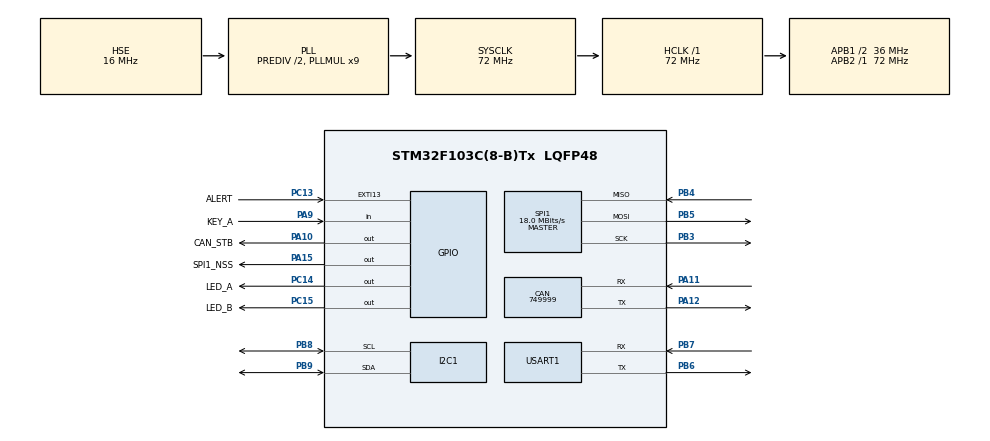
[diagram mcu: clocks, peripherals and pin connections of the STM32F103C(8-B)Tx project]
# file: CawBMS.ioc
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CAN.CalculateBaudRate=749999
CAN.CalculateTimeBit=1333
CAN.CalculateTimeQuantum=444.44444444444446
Mcu.Family=STM32F1
Mcu.Name=STM32F103C(8-B)Tx
Mcu.Package=LQFP48
NVIC.PriorityGroup=NVIC_PRIORITYGROUP_4
PA10.GPIO_Label=CAN_STB
PA10.PinState=GPIO_PIN_SET
PA10.Signal=GPIO_Output
PA11.Mode=CAN_Activate
PA11.Signal=CAN_RX
PA12.Mode=CAN_Activate
PA12.Signal=CAN_TX
PA13.Mode=Serial_Wire
PA13.Signal=SYS_JTMS-SWDIO
PA14.Mode=Serial_Wire
PA14.Signal=SYS_JTCK-SWCLK
PA15.GPIO_Label=SPI1_NSS
PA15.Signal=GPIO_Output
PA9.GPIO_Label=KEY_A
PA9.GPIO_PuPd=GPIO_PULLUP
PA9.Signal=GPIO_Input
PB3.Mode=Full_Duplex_Master
PB3.Signal=SPI1_SCK
PB4.Mode=Full_Duplex_Master
PB4.Signal=SPI1_MISO
PB5.Mode=Full_Duplex_Master
PB5.Signal=SPI1_MOSI
PB6.Mode=Asynchronous
PB6.Signal=USART1_TX
PB7.Mode=Asynchronous
PB7.Signal=USART1_RX
PB8.GPIO_Speed=GPIO_SPEED_FREQ_HIGH
PB8.Mode=I2C
PB8.Signal=I2C1_SCL
PB9.GPIO_Speed=GPIO_SPEED_FREQ_HIGH
PB9.Mode=I2C
PB9.Signal=I2C1_SDA
PC13-TAMPER-RTC.GPIO_Label=ALERT
PC13-TAMPER-RTC.Signal=GPXTI13
PC14-OSC32_IN.GPIO_Label=LED_A
PC14-OSC32_IN.PinState=GPIO_PIN_SET
PC14-OSC32_IN.Signal=GPIO_Output
PC15-OSC32_OUT.GPIO_Label=LED_B
PC15-OSC32_OUT.PinState=GPIO_PIN_SET
PC15-OSC32_OUT.Signal=GPIO_Output
PD0-OSC_IN.Mode=HSE-External-Oscillator
PD0-OSC_IN.Signal=RCC_OSC_IN
PD1-OSC_OUT.Mode=HSE-External-Oscillator
PD1-OSC_OUT.Signal=RCC_OSC_OUT
ProjectManager.HeapSize=0x200
ProjectManager.StackSize=0x400
ProjectManager.TargetToolchain=Makefile
RCC.AHBFreq_Value=72000000
RCC.APB1CLKDivider=RCC_HCLK_DIV2
RCC.APB1Freq_Value=36000000
RCC.APB1TimFreq_Value=72000000
RCC.APB2Freq_Value=72000000
RCC.APB2TimFreq_Value=72000000
RCC.HCLKFreq_Value=72000000
RCC.HSEDivPLL=RCC_HSE_PREDIV_DIV2
RCC.HSE_VALUE=16000000
RCC.PLLMUL=RCC_PLL_MUL9
RCC.PLLSourceVirtual=RCC_PLLSOURCE_HSE
RCC.SYSCLKFreq_VALUE=72000000
RCC.SYSCLKSource=RCC_SYSCLKSOURCE_PLLCLK
RCC.USBFreq_Value=72000000
SPI1.BaudRatePrescaler=SPI_BAUDRATEPRESCALER_4
SPI1.CalculateBaudRate=18.0 MBits/s
SPI1.Direction=SPI_DIRECTION_2LINES
SPI1.Mode=SPI_MODE_MASTER
SPI1.VirtualType=VM_MASTER
USART1.VirtualMode=VM_ASYNC
board=custom

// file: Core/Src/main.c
/* USER CODE BEGIN Header */
/**
 ******************************************************************************
 * @file           : main.c
 * @brief          : Main program body
 ******************************************************************************
 * @attention
 *
 * Copyright (c) 2023 STMicroelectronics.
 * All rights reserved.
 *
 * This software is licensed under terms that can be found in the LICENSE file
 * in the root directory of this software component.
 * If no LICENSE file comes with this software, it is provided AS-IS.
 *
 ******************************************************************************
 */
/* USER CODE END Header */
#include "main.h"

#include "can.h"
#include "gpio.h"
#include "i2c.h"
#include "spi.h"
#include "usart.h"

/* USER CODE BEGIN Includes */
#include "bq76920.h"
#include "caw_status.h"
#include "i2c.h"
#include "log.h"
/* USER CODE END Includes */

void SystemClock_Config(void);

int main(void) {

  /* MCU Configuration--------------------------------------------------------*/

  /* Reset of all peripherals, Initializes the Flash interface and the Systick.
   */
  HAL_Init();

  /* Configure the system clock */
  SystemClock_Config();

  /* Initialize all configured peripherals */
  MX_GPIO_Init();
  MX_CAN_Init();
  MX_I2C1_Init();
  MX_USART1_UART_Init();
  MX_SPI1_Init();

  /* Infinite loop */
  /* USER CODE BEGIN WHILE */
  BQ76920_T afe;
  BQ76920_Init(&afe, &hi2c1);
  while (1) {
    HAL_GPIO_TogglePin(LED_A_GPIO_Port, LED_A_Pin);
    BQ76920_UpdateCellVoltage(&afe);
    CAW_LOG_DEBUG("c1: %f c2: %f c3: %f c4: %f c5 %f", afe.CellVoltage[0],
                  afe.CellVoltage[1], afe.CellVoltage[2], afe.CellVoltage[3],
                  afe.CellVoltage[4]);
    HAL_Delay(500);
    /* USER CODE END WHILE */

  }
}

void SystemClock_Config(void) {
  RCC_OscInitTypeDef RCC_OscInitStruct = {0};
  RCC_ClkInitTypeDef RCC_ClkInitStruct = {0};

  /** Initializes the RCC Oscillators according to the specified parameters
   * in the RCC_OscInitTypeDef structure.
   */
  RCC_OscInitStruct.OscillatorType = RCC_OSCILLATORTYPE_HSE;
  RCC_OscInitStruct.HSEState = RCC_HSE_ON;
  RCC_OscInitStruct.HSEPredivValue = RCC_HSE_PREDIV_DIV2;
  RCC_OscInitStruct.HSIState = RCC_HSI_ON;
  RCC_OscInitStruct.PLL.PLLState = RCC_PLL_ON;
  RCC_OscInitStruct.PLL.PLLSource = RCC_PLLSOURCE_HSE;
  RCC_OscInitStruct.PLL.PLLMUL = RCC_PLL_MUL9;
  if (HAL_RCC_OscConfig(&RCC_OscInitStruct) != HAL_OK) {
    Error_Handler();
  }

  /** Initializes the CPU, AHB and APB buses clocks
   */
  RCC_ClkInitStruct.ClockType = RCC_CLOCKTYPE_HCLK | RCC_CLOCKTYPE_SYSCLK |
                                RCC_CLOCKTYPE_PCLK1 | RCC_CLOCKTYPE_PCLK2;
  RCC_ClkInitStruct.SYSCLKSource = RCC_SYSCLKSOURCE_PLLCLK;
  RCC_ClkInitStruct.AHBCLKDivider = RCC_SYSCLK_DIV1;
  RCC_ClkInitStruct.APB1CLKDivider = RCC_HCLK_DIV2;
  RCC_ClkInitStruct.APB2CLKDivider = RCC_HCLK_DIV1;

  if (HAL_RCC_ClockConfig(&RCC_ClkInitStruct, FLASH_LATENCY_2) != HAL_OK) {
    Error_Handler();
  }
}

void Error_Handler(void) {
  __disable_irq();
  while (1) {
  }
}

#ifdef USE_FULL_ASSERT
/**
 * @brief  Reports the name of the source file and the source line number
 *         where the assert_param error has occurred.
 * @param  file: pointer to the source file name
 * @param  line: assert_param error line source number
 * @retval None
 */
void assert_failed(uint8_t *file, uint32_t line) {
  /* USER CODE BEGIN 6 */
  /* User can add his own implementation to report the file name and line
     number, ex: printf("Wrong parameters value: file %s on line %d\r\n", file,
     line) */
  /* USER CODE END 6 */
}
#endif /* USE_FULL_ASSERT */
